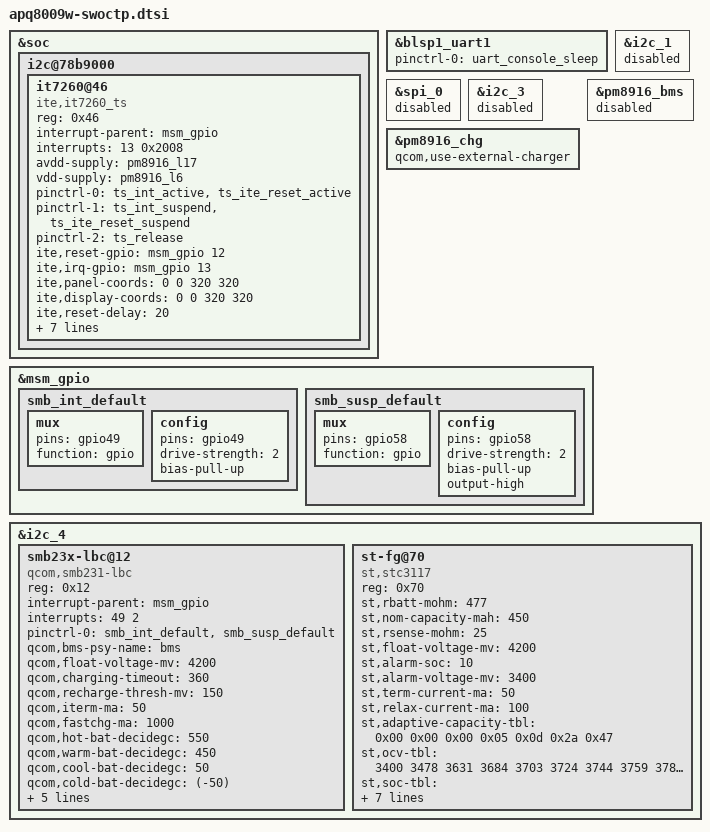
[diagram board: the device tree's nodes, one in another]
/*
 * Copyright (c) 2016, The Linux Foundation. All rights reserved.
 *
 * This program is free software; you can redistribute it and/or modify
 * it under the terms of the GNU General Public License version 2 and
 * only version 2 as published by the Free Software Foundation.
 *
 * This program is distributed in the hope that it will be useful,
 * but WITHOUT ANY WARRANTY; without even the implied warranty of
 * MERCHANTABILITY or FITNESS FOR A PARTICULAR PURPOSE.  See the
 * GNU General Public License for more details.
 */

#include "msm8909-mtp.dtsi"
#include "msm8909w-gpu.dtsi"
#include "msm8909-pm8916.dtsi"
#include "msm8909-pm8916-mtp.dtsi"
#include "msm8909w.dtsi"
#include "apq8009w-memory.dtsi"

&soc {
	i2c@78b9000 { /* BLSP1 QUP5 */
		/delete-node/ synaptics@20;

		it7260@46 {
			compatible = "ite,it7260_ts";
			reg = <0x46>;
			interrupt-parent = <&msm_gpio>;
			interrupts = <13 0x2008>;
			avdd-supply = <&pm8916_l17>;
			vdd-supply = <&pm8916_l6>;
			/* pins used by touchscreen */
			pinctrl-names = "pmx_ts_active","pmx_ts_suspend",
							"pmx_ts_release";
			pinctrl-0 = <&ts_int_active &ts_ite_reset_active>;
			pinctrl-1 = <&ts_int_suspend &ts_ite_reset_suspend>;
			pinctrl-2 = <&ts_release>;
			ite,reset-gpio = <&msm_gpio 12 0x00>;
			ite,irq-gpio = <&msm_gpio 13 0x2008>;
			ite,panel-coords = <0 0 320 320>;
			ite,display-coords = <0 0 320 320>;
			ite,reset-delay = <20>;
			ite,num-fingers = <2>;
			ite,wakeup;
			ite,palm-detect-en;
			ite,palm-detect-keycode = <142>;
			ite,fw-name = "it7260_fw_050D0014.bin";
			ite,cfg-name = "it7260_cfg_62011E01.bin";
			ite,avdd-lpm-cur = <3000>;
		};
	};
};

&blsp1_uart1 {
	status = "ok";
	pinctrl-names = "default";
	pinctrl-0 = <&uart_console_sleep>;
};

&i2c_1 {
	status = "disabled";
};

&spi_0 {
	status = "disabled";
};

&i2c_3 {
	status = "disabled";
};

/* Charger/FG configuration */
&pm8916_chg {
	qcom,use-external-charger;
};

&pm8916_bms {
	status = "disabled";
};

&msm_gpio {
	/* Delete gpio58 configuration */
	/delete-node/ tpiu_seta_14;
	/delete-node/ smb_int_pin;
	smb_int_default: smb_int_default {
		mux {
			pins = "gpio49";
			function = "gpio";
		};
		config {
			pins = "gpio49";
			drive-strength = <2>;   /* 2 MA */
			bias-pull-up;           /* PULL UP*/
		};
	};

	smb_susp_default: smb_susp_default {
		mux {
			pins = "gpio58";
			function ="gpio";
		};
		config {
			pins = "gpio58";
			drive-strength = <2>;   /* 2 MA */
			bias-pull-up;           /* PULL UP*/
			output-high;
		};
	};
};

&i2c_4 {
	status = "ok";
	smb23x-lbc@12 {
		compatible = "qcom,smb231-lbc";
		reg = <0x12>;
		interrupt-parent = <&msm_gpio>;
		interrupts = <49 2>;
		pinctrl-names = "default";
		pinctrl-0 = <&smb_int_default &smb_susp_default>;

		qcom,bms-psy-name = "bms";
		qcom,float-voltage-mv = <4200>;
		qcom,charging-timeout = <360>;
		qcom,recharge-thresh-mv = <150>;
		qcom,iterm-ma = <50>;
		qcom,fastchg-ma = <1000>;
		qcom,hot-bat-decidegc = <550>;
		qcom,warm-bat-decidegc = <450>;
		qcom,cool-bat-decidegc = <50>;
		qcom,cold-bat-decidegc = <(-50)>;
		qcom,soft-temp-vfloat-comp-mv = <200>;
		qcom,soft-temp-current-comp-ma = <400>;
		qcom,chg-inhibit-disabled;
		qcom,apsd-disabled;
		qcom,thermal-mitigation = <1500 900 500 100>;
	};

	st-fg@70 {
		compatible = "st,stc3117";
		reg = <0x70>;
		st,rbatt-mohm = <477>;
		st,nom-capacity-mah = <450>;
		st,rsense-mohm = <25>;
		st,float-voltage-mv = <4200>;
		st,alarm-soc = <10>;
		st,alarm-voltage-mv = <3400>;
		st,term-current-ma = <50>;
		st,relax-current-ma = <100>;
		st,adaptive-capacity-tbl =
			/bits/ 16 <0x00 0x00 0x00 0x05 0x0d 0x2a 0x47>;
		st,ocv-tbl =
			/bits/ 16 <3400 3478 3631 3684 3703 3724
				3744 3759 3782 3808 3850 3884
				3922 3984 4066 4167>;
		st,soc-tbl = /bits/ 8 <0 3 6 10 15 20
					25 30 40 50 60 65
					70 80 90 100>;
		st,vmtemp-tbl =
			/bits/ 16 <0x55 0x5a 0x64 0xa0 0x140 0x1b8 0x348>;
		st,temp-tbl =
			/bits/ 16 <60 40 25 10 0 (-10) (-20)>;

		st,empty-soc-uv = <3300000>;
		qcom,fg-vadc = <&pm8916_vadc>;
		qcom,fg-adc_tm = <&pm8916_adc_tm>;
	};
};
